# RZG2L register map
Vendor: Renesas; Series: All Chips; File version: x.xx
Registers are 32-bit, access not given, no defined reset value unless marked. A register's access mark holds for its fields unless they carry their own. Offsets are from the block's base; [hi:lo] are bit positions; {n}, {i} and the like mark numbered series; 'fields as' and 'values as' point back to an identical list.

## CPG
Base 0x41010000
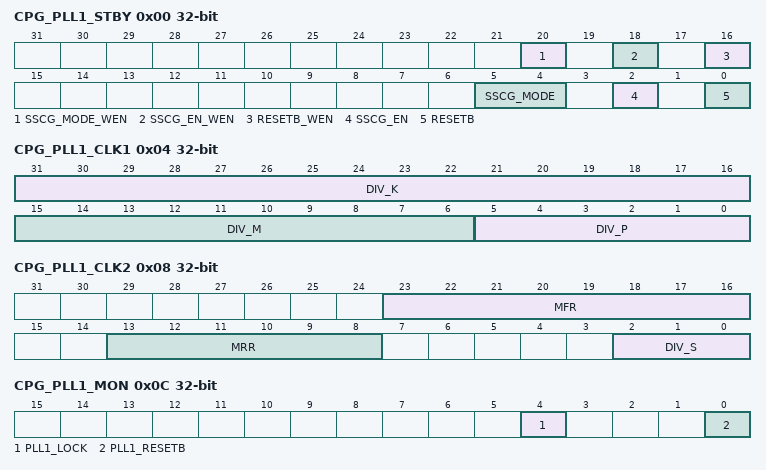
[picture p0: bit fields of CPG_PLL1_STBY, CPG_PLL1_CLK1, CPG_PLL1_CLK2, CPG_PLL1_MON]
0x00 CPG_PLL1_STBY
  [20] SSCG_MODE_WEN, [18] SSCG_EN_WEN, [16] RESETB_WEN, [5:4] SSCG_MODE, [2] SSCG_EN, [0] RESETB
0x04 CPG_PLL1_CLK1
  [31:16] DIV_K, [15:6] DIV_M, [5:0] DIV_P
0x08 CPG_PLL1_CLK2
  [23:16] MFR, [13:8] MRR, [2:0] DIV_S
0x0C CPG_PLL1_MON
  [4] PLL1_LOCK, [0] PLL1_RESETB
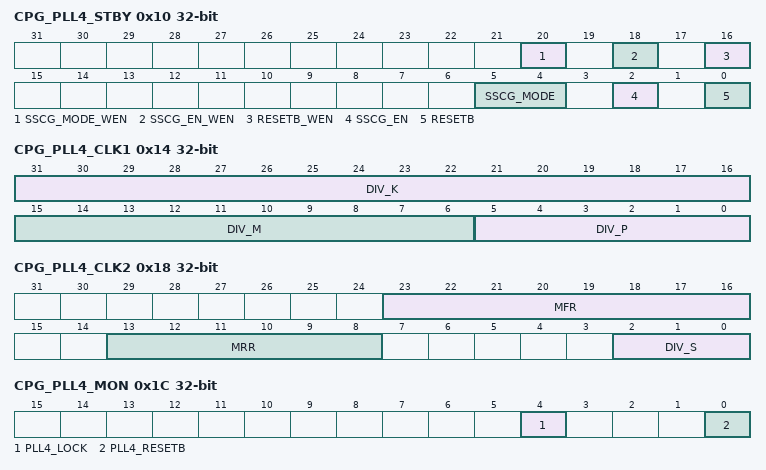
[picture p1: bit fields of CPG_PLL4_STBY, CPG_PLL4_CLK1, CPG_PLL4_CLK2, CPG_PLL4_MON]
0x10 CPG_PLL4_STBY
  fields as CPG_PLL1_STBY
0x14 CPG_PLL4_CLK1
  [31:16] DIV_K, [15:6] DIV_M, [5:0] DIV_P
0x18 CPG_PLL4_CLK2
  [23:16] MFR, [13:8] MRR, [2:0] DIV_S
0x1C CPG_PLL4_MON
  [4] PLL4_LOCK, [0] PLL4_RESETB
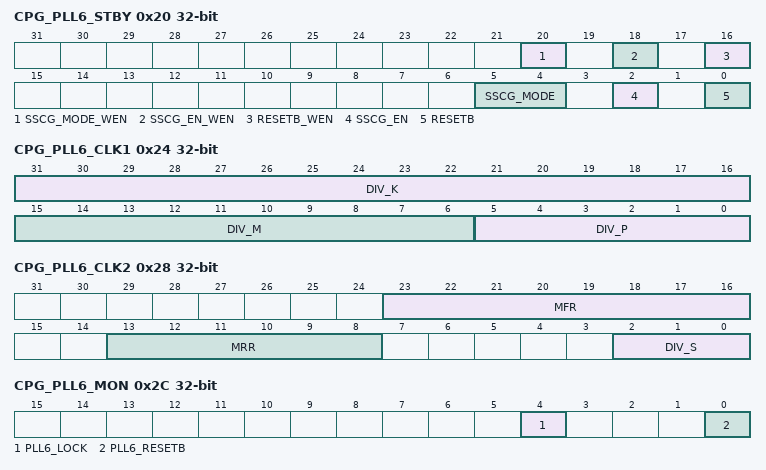
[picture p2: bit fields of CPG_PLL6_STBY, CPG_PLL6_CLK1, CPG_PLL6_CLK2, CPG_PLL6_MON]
0x20 CPG_PLL6_STBY
  fields as CPG_PLL1_STBY
0x24 CPG_PLL6_CLK1
  [31:16] DIV_K, [15:6] DIV_M, [5:0] DIV_P
0x28 CPG_PLL6_CLK2
  [23:16] MFR, [13:8] MRR, [2:0] DIV_S
0x2C CPG_PLL6_MON
  [4] PLL6_LOCK, [0] PLL6_RESETB
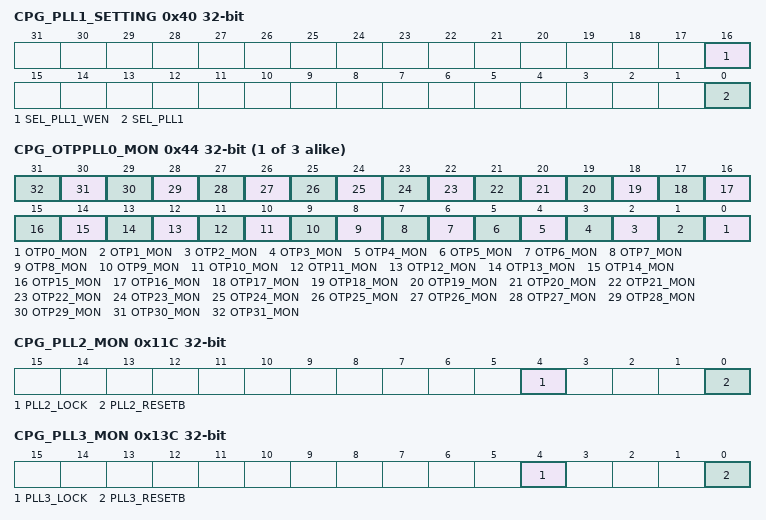
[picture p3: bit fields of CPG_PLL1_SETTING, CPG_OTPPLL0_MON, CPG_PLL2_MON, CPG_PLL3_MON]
0x40 CPG_PLL1_SETTING
  [16] SEL_PLL1_WEN, [0] SEL_PLL1
{0x44+4i} CPG_OTPPLL{i}_MON (i=0..2)
  [n] OTP{n}_MON (n=0..31)
0x11C CPG_PLL2_MON
  [4] PLL2_LOCK, [0] PLL2_RESETB
0x13C CPG_PLL3_MON
  [4] PLL3_LOCK, [0] PLL3_RESETB
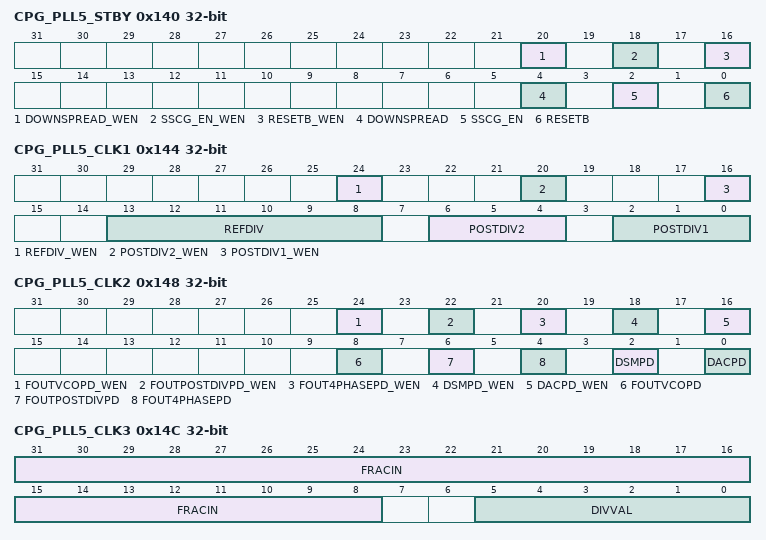
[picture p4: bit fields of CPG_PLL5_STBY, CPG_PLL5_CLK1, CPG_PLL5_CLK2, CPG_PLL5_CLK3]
0x140 CPG_PLL5_STBY
  [20] DOWNSPREAD_WEN, [18] SSCG_EN_WEN, [16] RESETB_WEN, [4] DOWNSPREAD, [2] SSCG_EN, [0] RESETB
0x144 CPG_PLL5_CLK1
  [24] REFDIV_WEN, [20] POSTDIV2_WEN, [16] POSTDIV1_WEN, [13:8] REFDIV, [6:4] POSTDIV2, [2:0] POSTDIV1
0x148 CPG_PLL5_CLK2
  [24] FOUTVCOPD_WEN, [22] FOUTPOSTDIVPD_WEN, [20] FOUT4PHASEPD_WEN, [18] DSMPD_WEN, [16] DACPD_WEN, [8] FOUTVCOPD, [6] FOUTPOSTDIVPD, [4] FOUT4PHASEPD, [2] DSMPD, [0] DACPD
0x14C CPG_PLL5_CLK3
  [31:8] FRACIN, [5:0] DIVVAL
0x150 CPG_PLL5_CLK4
  [27:16] INTIN
0x154 CPG_PLL5_CLK5
  [4:0] SPREAD
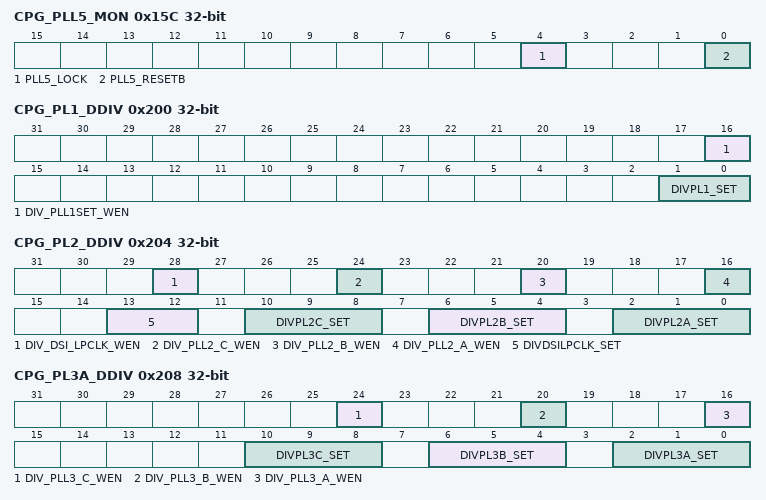
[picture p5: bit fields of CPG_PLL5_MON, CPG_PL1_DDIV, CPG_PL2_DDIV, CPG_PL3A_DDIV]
0x15C CPG_PLL5_MON
  [4] PLL5_LOCK, [0] PLL5_RESETB
0x200 CPG_PL1_DDIV
  [16] DIV_PLL1SET_WEN, [1:0] DIVPL1_SET
0x204 CPG_PL2_DDIV
  [28] DIV_DSI_LPCLK_WEN, [24] DIV_PLL2_C_WEN, [20] DIV_PLL2_B_WEN, [16] DIV_PLL2_A_WEN, [13:12] DIVDSILPCLK_SET, [10:8] DIVPL2C_SET, [6:4] DIVPL2B_SET, [2:0] DIVPL2A_SET
0x208 CPG_PL3A_DDIV
  [24] DIV_PLL3_C_WEN, [20] DIV_PLL3_B_WEN, [16] DIV_PLL3_A_WEN, [10:8] DIVPL3C_SET, [6:4] DIVPL3B_SET, [2:0] DIVPL3A_SET
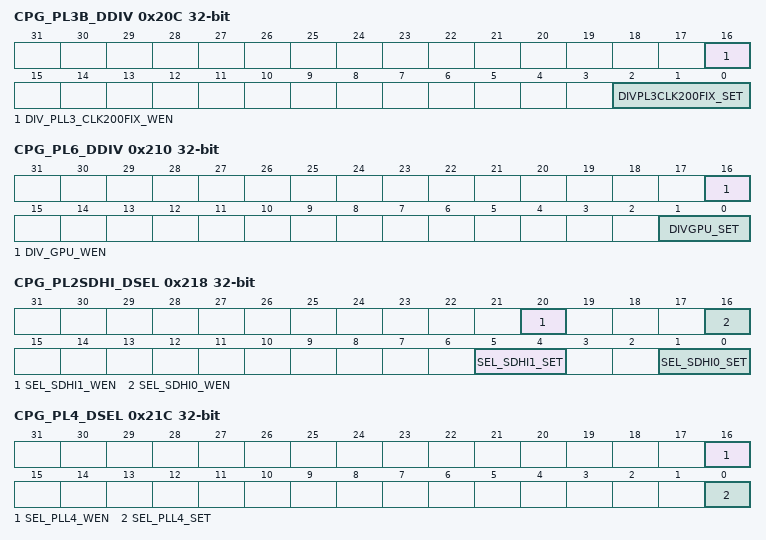
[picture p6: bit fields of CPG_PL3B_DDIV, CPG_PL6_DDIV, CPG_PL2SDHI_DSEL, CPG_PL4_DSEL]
0x20C CPG_PL3B_DDIV
  [16] DIV_PLL3_CLK200FIX_WEN, [2:0] DIVPL3CLK200FIX_SET
0x210 CPG_PL6_DDIV
  [16] DIV_GPU_WEN, [1:0] DIVGPU_SET
0x218 CPG_PL2SDHI_DSEL
  [20] SEL_SDHI1_WEN, [16] SEL_SDHI0_WEN, [5:4] SEL_SDHI1_SET, [1:0] SEL_SDHI0_SET
0x21C CPG_PL4_DSEL
  [16] SEL_PLL4_WEN, [0] SEL_PLL4_SET
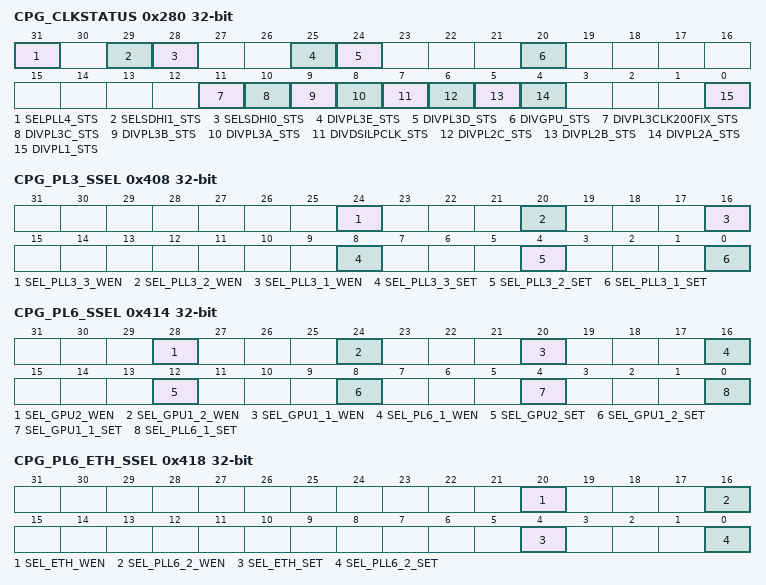
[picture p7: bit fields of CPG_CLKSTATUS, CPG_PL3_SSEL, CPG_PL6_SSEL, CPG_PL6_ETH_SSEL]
0x280 CPG_CLKSTATUS
  [31] SELPLL4_STS, [29] SELSDHI1_STS, [28] SELSDHI0_STS, [25] DIVPL3E_STS, [24] DIVPL3D_STS, [20] DIVGPU_STS, [11] DIVPL3CLK200FIX_STS, [10] DIVPL3C_STS, [9] DIVPL3B_STS, [8] DIVPL3A_STS, [7] DIVDSILPCLK_STS, [6] DIVPL2C_STS, [5] DIVPL2B_STS, [4] DIVPL2A_STS, [0] DIVPL1_STS
0x408 CPG_PL3_SSEL
  [24] SEL_PLL3_3_WEN, [20] SEL_PLL3_2_WEN, [16] SEL_PLL3_1_WEN, [8] SEL_PLL3_3_SET, [4] SEL_PLL3_2_SET, [0] SEL_PLL3_1_SET
0x414 CPG_PL6_SSEL
  [28] SEL_GPU2_WEN, [24] SEL_GPU1_2_WEN, [20] SEL_GPU1_1_WEN, [16] SEL_PL6_1_WEN, [12] SEL_GPU2_SET, [8] SEL_GPU1_2_SET, [4] SEL_GPU1_1_SET, [0] SEL_PLL6_1_SET
0x418 CPG_PL6_ETH_SSEL
  [20] SEL_ETH_WEN, [16] SEL_PLL6_2_WEN, [4] SEL_ETH_SET, [0] SEL_PLL6_2_SET
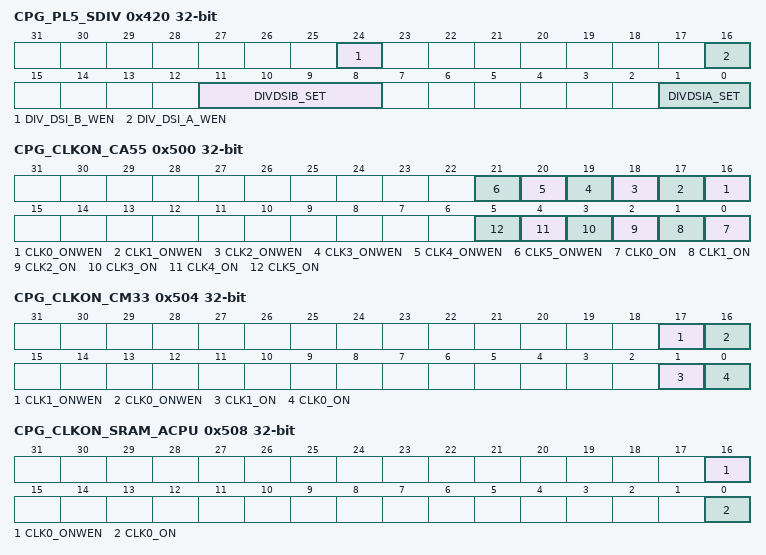
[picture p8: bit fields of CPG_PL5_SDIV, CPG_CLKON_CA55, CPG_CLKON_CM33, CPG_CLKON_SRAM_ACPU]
0x420 CPG_PL5_SDIV
  [24] DIV_DSI_B_WEN, [16] DIV_DSI_A_WEN, [11:8] DIVDSIB_SET, [1:0] DIVDSIA_SET
0x500 CPG_CLKON_CA55
  [n+16] CLK{n}_ONWEN (n=0..5), [n] CLK{n}_ON (n=0..5)
0x504 CPG_CLKON_CM33
  [17] CLK1_ONWEN, [16] CLK0_ONWEN, [1] CLK1_ON, [0] CLK0_ON
0x508 CPG_CLKON_SRAM_ACPU
  [16] CLK0_ONWEN, [0] CLK0_ON
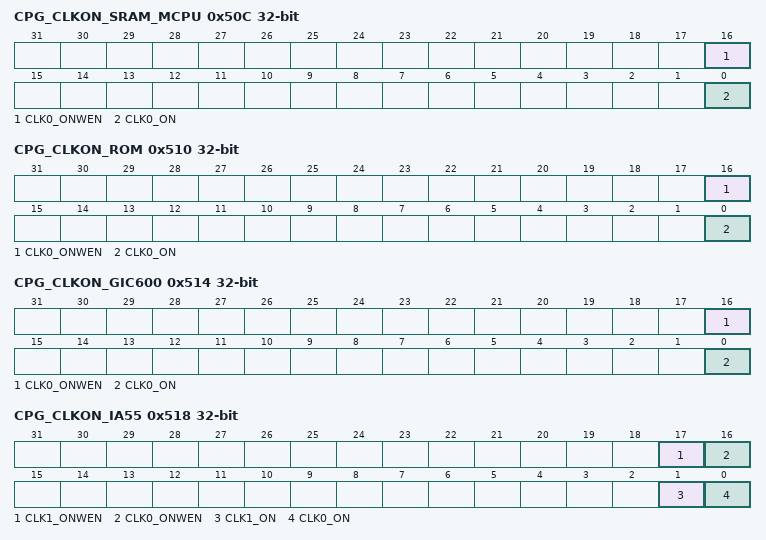
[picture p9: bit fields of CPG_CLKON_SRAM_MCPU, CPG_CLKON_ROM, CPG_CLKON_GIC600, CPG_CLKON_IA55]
0x50C CPG_CLKON_SRAM_MCPU
  [16] CLK0_ONWEN, [0] CLK0_ON
0x510 CPG_CLKON_ROM
  [16] CLK0_ONWEN, [0] CLK0_ON
0x514 CPG_CLKON_GIC600
  [16] CLK0_ONWEN, [0] CLK0_ON
0x518 CPG_CLKON_IA55
  [17] CLK1_ONWEN, [16] CLK0_ONWEN, [1] CLK1_ON, [0] CLK0_ON
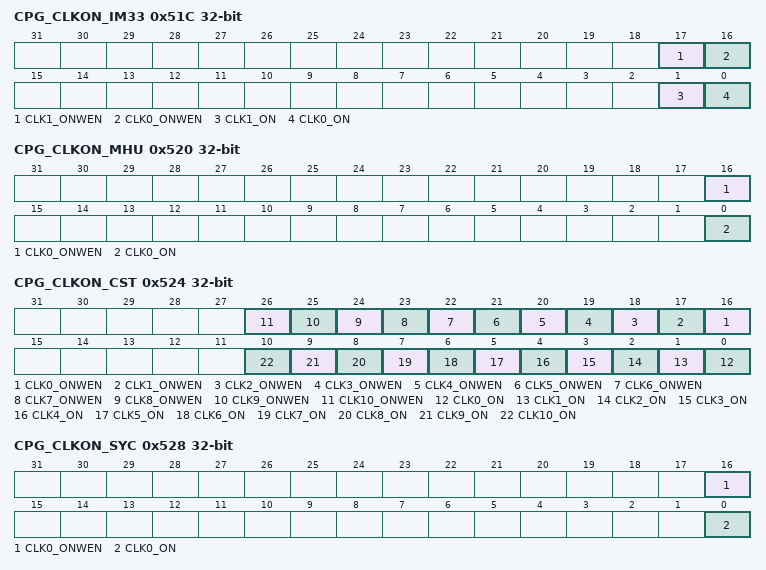
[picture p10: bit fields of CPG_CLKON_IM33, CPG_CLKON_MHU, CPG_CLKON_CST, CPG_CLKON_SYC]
0x51C CPG_CLKON_IM33
  [17] CLK1_ONWEN, [16] CLK0_ONWEN, [1] CLK1_ON, [0] CLK0_ON
0x520 CPG_CLKON_MHU
  [16] CLK0_ONWEN, [0] CLK0_ON
0x524 CPG_CLKON_CST
  [n+16] CLK{n}_ONWEN (n=0..10), [n] CLK{n}_ON (n=0..10)
0x528 CPG_CLKON_SYC
  [16] CLK0_ONWEN, [0] CLK0_ON
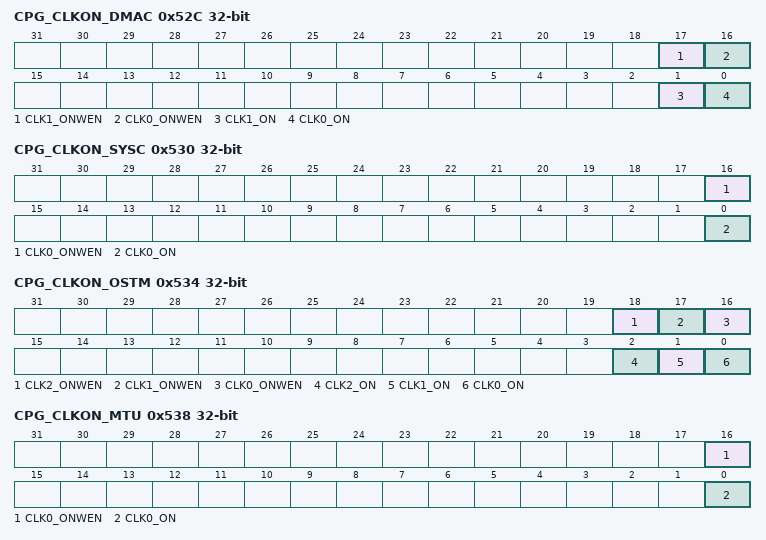
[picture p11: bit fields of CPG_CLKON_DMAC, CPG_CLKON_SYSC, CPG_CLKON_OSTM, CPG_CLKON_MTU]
0x52C CPG_CLKON_DMAC
  [17] CLK1_ONWEN, [16] CLK0_ONWEN, [1] CLK1_ON, [0] CLK0_ON
0x530 CPG_CLKON_SYSC
  [16] CLK0_ONWEN, [0] CLK0_ON
0x534 CPG_CLKON_OSTM
  [18] CLK2_ONWEN, [17] CLK1_ONWEN, [16] CLK0_ONWEN, [2] CLK2_ON, [1] CLK1_ON, [0] CLK0_ON
0x538 CPG_CLKON_MTU
  [16] CLK0_ONWEN, [0] CLK0_ON
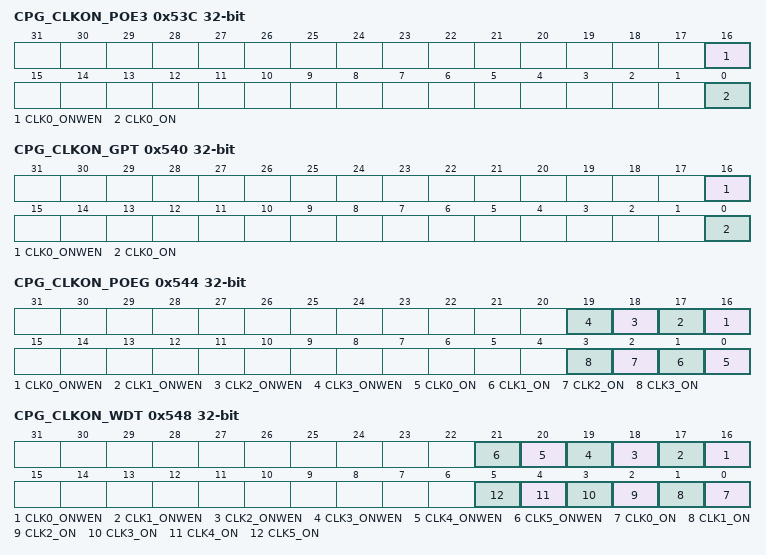
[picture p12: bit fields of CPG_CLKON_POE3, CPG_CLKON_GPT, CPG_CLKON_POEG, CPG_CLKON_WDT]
0x53C CPG_CLKON_POE3
  [16] CLK0_ONWEN, [0] CLK0_ON
0x540 CPG_CLKON_GPT
  [16] CLK0_ONWEN, [0] CLK0_ON
0x544 CPG_CLKON_POEG
  [n+16] CLK{n}_ONWEN (n=0..3), [n] CLK{n}_ON (n=0..3)
0x548 CPG_CLKON_WDT
  [n+16] CLK{n}_ONWEN (n=0..5), [n] CLK{n}_ON (n=0..5)
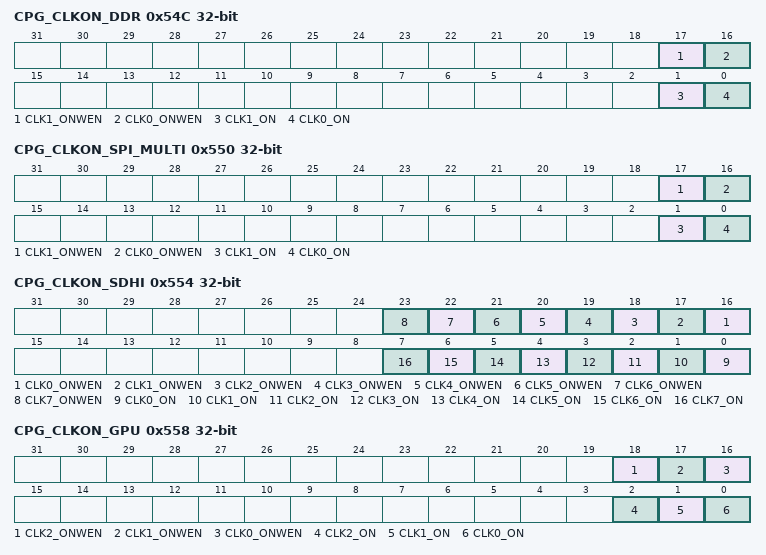
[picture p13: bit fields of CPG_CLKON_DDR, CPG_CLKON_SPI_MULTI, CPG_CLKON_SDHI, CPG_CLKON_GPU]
0x54C CPG_CLKON_DDR
  [17] CLK1_ONWEN, [16] CLK0_ONWEN, [1] CLK1_ON, [0] CLK0_ON
0x550 CPG_CLKON_SPI_MULTI
  [17] CLK1_ONWEN, [16] CLK0_ONWEN, [1] CLK1_ON, [0] CLK0_ON
0x554 CPG_CLKON_SDHI
  [n+16] CLK{n}_ONWEN (n=0..7), [n] CLK{n}_ON (n=0..7)
0x558 CPG_CLKON_GPU
  fields as CPG_CLKON_OSTM
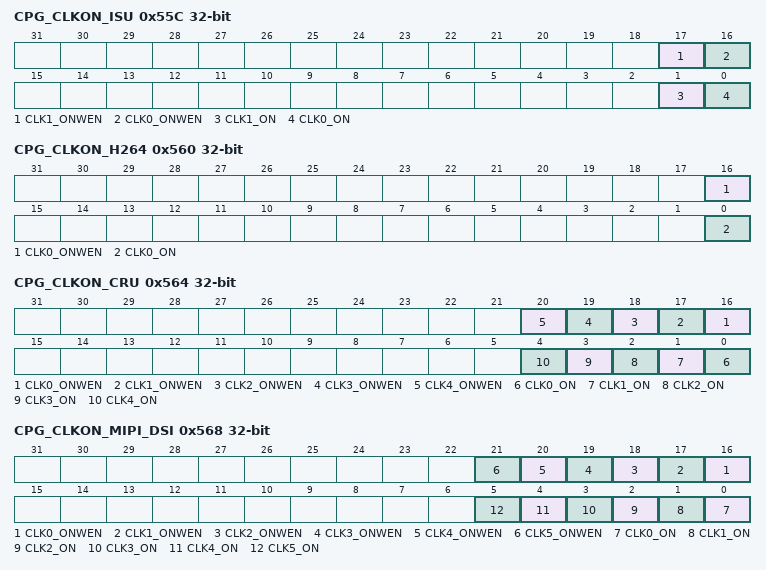
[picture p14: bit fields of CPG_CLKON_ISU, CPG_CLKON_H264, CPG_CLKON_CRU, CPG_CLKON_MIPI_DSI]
0x55C CPG_CLKON_ISU
  [17] CLK1_ONWEN, [16] CLK0_ONWEN, [1] CLK1_ON, [0] CLK0_ON
0x560 CPG_CLKON_H264
  [16] CLK0_ONWEN, [0] CLK0_ON
0x564 CPG_CLKON_CRU
  [n+16] CLK{n}_ONWEN (n=0..4), [n] CLK{n}_ON (n=0..4)
0x568 CPG_CLKON_MIPI_DSI
  [n+16] CLK{n}_ONWEN (n=0..5), [n] CLK{n}_ON (n=0..5)
0x56C CPG_CLKON_LCDC
  [17] CLK1_ONWEN, [16] CLK0_ONWEN, [1] CLK1_ON, [0] CLK0_ON
0x570 CPG_CLKON_SSIF
  [n+16] CLK{n}_ONWEN (n=0..7), [n] CLK{n}_ON (n=0..7)
0x574 CPG_CLKON_SRC
  [16] CLK0_ONWEN, [0] CLK0_ON
0x578 CPG_CLKON_USB
  [n+16] CLK{n}_ONWEN (n=0..3), [n] CLK{n}_ON (n=0..3)
0x57C CPG_CLKON_ETH
  [17] CLK1_ONWEN, [16] CLK0_ONWEN, [1] CLK1_ON, [0] CLK0_ON
0x580 CPG_CLKON_I2C
  [n+16] CLK{n}_ONWEN (n=0..3), [n] CLK{n}_ON (n=0..3)
0x584 CPG_CLKON_SCIF
  [n+16] CLK{n}_ONWEN (n=0..4), [n] CLK{n}_ON (n=0..4)
0x588 CPG_CLKON_SCI
  [17] CLK1_ONWEN, [16] CLK0_ONWEN, [1] CLK1_ON, [0] CLK0_ON
0x58C CPG_CLKON_IRDA
  [16] CLK0_ONWEN, [0] CLK0_ON
0x590 CPG_CLKON_RSPI
  fields as CPG_CLKON_OSTM
0x594 CPG_CLKON_CANFD
  [16] CLK0_ONWEN, [0] CLK0_ON
0x598 CPG_CLKON_GPIO
  [16] CLK0_ONWEN, [0] CLK0_ON
0x59C CPG_CLKON_TSIPG
  [17] CLK1_ONWEN, [16] CLK0_ONWEN, [1] CLK1_ON, [0] CLK0_ON
0x5A4 CPG_CLKON_OTP
  [17] CLK1_ONWEN, [16] CLK0_ONWEN, [1] CLK1_ON, [0] CLK0_ON
0x5A8 CPG_CLKON_ADC
  [17] CLK1_ONWEN, [16] CLK0_ONWEN, [1] CLK1_ON, [0] CLK0_ON
0x5AC CPG_CLKON_TSU
  [16] CLK0_ONWEN, [0] CLK0_ON
0x5B0 CPG_CLKON_BBGU
  [16] CLK0_ONWEN, [0] CLK0_ON
0x5B4 CPG_CLKON_AXI_ACPU_BUS
  [n+16] CLK{n}_ONWEN (n=0..3), [n] CLK{n}_ON (n=0..3)
0x5B8 CPG_CLKON_AXI_MCPU_BUS
  [n+16] CLK{n}_ONWEN (n=0..10), [n] CLK{n}_ON (n=0..10)
0x5BC CPG_CLKON_AXI_COM_BUS
  [17] CLK1_ONWEN, [16] CLK0_ONWEN, [1] CLK1_ON, [0] CLK0_ON
0x5C0 CPG_CLKON_AXI_VIDEO_BUS
  [17] CLK1_ONWEN, [16] CLK0_ONWEN, [1] CLK1_ON, [0] CLK0_ON
0x5C4 CPG_CLKON_PERI_COM
  [17] CLK1_ONWEN, [16] CLK0_ONWEN, [1] CLK1_ON, [0] CLK0_ON
0x5C8 CPG_CLKON_REG1_BUS
  [17] CLK1_ONWEN, [16] CLK0_ONWEN, [1] CLK1_ON, [0] CLK0_ON
0x5CC CPG_CLKON_REG0_BUS
  [n+16] CLK{n}_ONWEN (n=0..3), [n] CLK{n}_ON (n=0..3)
0x5D0 CPG_CLKON_PERI_CPU
  [n+16] CLK{n}_ONWEN (n=0..3), [n] CLK{n}_ON (n=0..3)
0x5D4 CPG_CLKON_PERI_VIDEO
  fields as CPG_CLKON_OSTM
0x5D8 CPG_CLKON_PERI_DDR
  [16] CLK0_ONWEN, [0] CLK0_ON
0x5DC CPG_CLKON_AXI_TZCDDR
  [n+16] CLK{n}_ONWEN (n=0..4), [n] CLK{n}_ON (n=0..4)
0x5E0 CPG_CLKON_MTGPGS
  [17] CLK1_ONWEN, [16] CLK0_ONWEN, [1] CLK1_ON, [0] CLK0_ON
0x5E4 CPG_CLKON_AXI_DEFAULT_SLV
  [16] CLK0_ONWEN, [0] CLK0_ON
0x680 CPG_CLKMON_CA55
  [n] CLK{n}_MON (n=0..5)
0x684 CPG_CLKMON_CM33
  [1] CLK1_MON, [0] CLK0_MON
0x688 CPG_CLKMON_SRAM_ACPU
  [0] CLK0_MON
0x68C CPG_CLKMON_SRAM_MCPU
  [0] CLK0_MON
0x690 CPG_CLKMON_ROM
  [0] CLK0_MON
0x694 CPG_CLKMON_GIC600
  [0] CLK0_MON
0x698 CPG_CLKMON_IA55
  [1] CLK1_MON, [0] CLK0_MON
0x69C CPG_CLKMON_IM33
  [1] CLK1_MON, [0] CLK0_MON
0x6A0 CPG_CLKMON_MHU
  [0] CLK0_MON
0x6A4 CPG_CLKMON_CST
  [n] CLK{n}_MON (n=0..10)
0x6A8 CPG_CLKMON_SYC
  [0] CLK0_MON
0x6AC CPG_CLKMON_DMAC
  [1] CLK1_MON, [0] CLK0_MON
0x6B0 CPG_CLKMON_SYSC
  [0] CLK0_MON
0x6B4 CPG_CLKMON_OSTM
  [2] CLK2_MON, [1] CLK1_MON, [0] CLK0_MON
0x6B8 CPG_CLKMON_MTU
  [0] CLK0_MON
0x6BC CPG_CLKMON_POE3
  [0] CLK0_MON
0x6C0 CPG_CLKMON_GPT
  [0] CLK0_MON
0x6C4 CPG_CLKMON_POEG
  [n] CLK{n}_MON (n=0..3)
0x6C8 CPG_CLKMON_WDT
  [n] CLK{n}_MON (n=0..7)
0x6CC CPG_CLKMON_DDR
  [1] CLK1_MON, [0] CLK0_MON
0x6D0 CPG_CLKMON_SPI_MULTI
  [1] CLK1_MON, [0] CLK0_MON
0x6D4 CPG_CLKMON_SDHI
  [n] CLK{n}_MON (n=0..7)
0x6D8 CPG_CLKMON_GPU
  [2] CLK2_MON, [1] CLK1_MON, [0] CLK0_MON
0x6DC CPG_CLKMON_ISU
  [1] CLK1_MON, [0] CLK0_MON
0x6E0 CPG_CLKMON_H264
  [0] CLK0_MON
0x6E4 CPG_CLKMON_CRU
  [n] CLK{n}_MON (n=0..4)
0x6E8 CPG_CLKMON_MIPI_DSI
  [n] CLK{n}_MON (n=0..5)
0x6EC CPG_CLKMON_LCDC
  [1] CLK1_MON, [0] CLK0_MON
0x6F0 CPG_CLKMON_SSIF
  [n] CLK{n}_MON (n=0..7)
0x6F4 CPG_CLKMON_SRC
  [0] CLK0_MON
0x6F8 CPG_CLKMON_USB
  [n] CLK{n}_MON (n=0..3)
0x6FC CPG_CLKMON_ETH
  [1] CLK1_MON, [0] CLK0_MON
0x700 CPG_CLKMON_I2C
  [n] CLK{n}_MON (n=0..3)
0x704 CPG_CLKMON_SCIF
  [n] CLK{n}_MON (n=0..4)
0x708 CPG_CLKMON_SCI
  [1] CLK1_MON, [0] CLK0_MON
0x70C CPG_CLKMON_IRDA
  [0] CLK0_MON
0x710 CPG_CLKMON_RSPI
  [2] CLK2_MON, [1] CLK1_MON, [0] CLK0_MON
0x714 CPG_CLKMON_CANFD
  [0] CLK0_MON
0x718 CPG_CLKMON_GPIO
  [0] CLK0_MON
0x71C CPG_CLKMON_TSIPG
  [1] CLK1_MON, [0] CLK0_MON
0x720 CPG_CLKMON_JAUTH
  [0] CLK0_MON
0x724 CPG_CLKMON_OTP
  [1] CLK1_MON, [0] CLK0_MON
0x728 CPG_CLKMON_ADC
  [1] CLK1_MON, [0] CLK0_MON
0x72C CPG_CLKMON_TSU
  [0] CLK0_MON
0x730 CPG_CLKMON_BBGU
  [0] CLK0_MON
0x734 CPG_CLKMON_AXI_ACPU_BUS
  [n] CLK{n}_MON (n=0..3)
0x738 CPG_CLKMON_AXI_MCPU_BUS
  [n] CLK{n}_MON (n=0..10)
0x73C CPG_CLKMON_AXI_COM_BUS
  [1] CLK1_MON, [0] CLK0_MON
0x740 CPG_CLKMON_AXI_VIDEO_BUS
  [1] CLK1_MON, [0] CLK0_MON
0x744 CPG_CLKMON_PERI_COM
  [1] CLK1_MON, [0] CLK0_MON
0x748 CPG_CLKMON_REG1_BUS
  [1] CLK1_MON, [0] CLK0_MON
0x74C CPG_CLKMON_REG0_BUS
  [n] CLK{n}_MON (n=0..3)
0x750 CPG_CLKMON_PERI_CPU
  [n] CLK{n}_MON (n=0..3)
0x754 CPG_CLKMON_PERI_VIDEO
  [2] CLK2_MON, [1] CLK1_MON, [0] CLK0_MON
0x758 CPG_CLKMON_PERI_DDR
  [0] CLK0_MON
0x75C CPG_CLKMON_AXI_TZCDDR
  [n] CLK{n}_MON (n=0..4)
0x760 CPG_CLKMON_MTGPGS
  [1] CLK1_MON, [0] CLK0_MON
0x764 CPG_CLKMON_AXI_DEFAULT_SLV
  [0] CLK0_MON
0x800 CPG_RST_CA55
  [n+16] UNIT{n}_RSTWEN (n=0..12), [n] UNIT{n}_RSTB (n=0..12)
0x804 CPG_RST_CM33
  [18] UNIT2_RSTWEN, [17] UNIT1_RSTWEN, [16] UNIT0_RSTWEN, [2] UNIT2_RSTB, [1] UNIT1_RSTB, [0] UNIT0_RSTB
0x808 CPG_RST_SRAM_ACPU
  [16] UNIT0_RSTWEN, [0] UNIT0_RSTB
0x80C CPG_RST_SRAM_MCPU
  [16] UNIT0_RSTWEN, [0] UNIT0_RSTB
0x810 CPG_RST_ROM
  [16] UNIT0_RSTWEN, [0] UNIT0_RSTB
0x814 CPG_RST_GIC600
  [17] UNIT1_RSTWEN, [16] UNIT0_RSTWEN, [1] UNIT1_RSTB, [0] UNIT0_RSTB
0x818 CPG_RST_IA55
  [16] UNIT0_RSTWEN, [0] UNIT0_RSTB
0x81C CPG_RST_IM33
  [16] UNIT0_RSTWEN, [0] UNIT0_RSTB
0x820 CPG_RST_MHU
  [16] UNIT0_RSTWEN, [0] UNIT0_RSTB
0x828 CPG_RST_SYC
  [16] UNIT0_RSTWEN, [0] UNIT0_RSTB
0x82C CPG_RST_DMAC
  [17] UNIT1_RSTWEN, [16] UNIT0_RSTWEN, [1] UNIT1_RSTB, [0] UNIT0_RSTB
0x830 CPG_RST_SYSC
  fields as CPG_RST_CM33
0x834 CPG_RST_OSTM
  fields as CPG_RST_CM33
0x838 CPG_RST_MTU
  [16] UNIT0_RSTWEN, [0] UNIT0_RSTB
0x83C CPG_RST_POE3
  [16] UNIT0_RSTWEN, [0] UNIT0_RSTB
0x840 CPG_RST_GPT
  [16] UNIT0_RSTWEN, [0] UNIT0_RSTB
0x844 CPG_RST_POEG
  [n+16] UNIT{n}_RSTWEN (n=0..3), [n] UNIT{n}_RSTB (n=0..3)
0x848 CPG_RST_WDT
  [n+16] UNIT{n}_RSTWEN (n=0..3), [n] UNIT{n}_RSTB (n=0..3)
0x84C CPG_RST_DDR
  [n+16] UNIT{n}_RSTWEN (n=0..6), [n] UNIT{n}_RSTB (n=0..6)
0x850 CPG_RST_SPI
  [16] UNIT0_RSTWEN, [0] UNIT0_RSTB
0x854 CPG_RST_SDHI
  [17] UNIT1_RSTWEN, [16] UNIT0_RSTWEN, [1] UNIT1_RSTB, [0] UNIT0_RSTB
0x858 CPG_RST_GPU
  fields as CPG_RST_CM33
0x85C CPG_RST_ISU
  [17] UNIT1_RSTWEN, [16] UNIT0_RSTWEN, [1] UNIT1_RSTB, [0] UNIT0_RSTB
0x860 CPG_RST_H264
  [17] UNIT1_RSTWEN, [16] UNIT0_RSTWEN, [1] UNIT1_RSTB, [0] UNIT0_RSTB
0x864 CPG_RST_CRU
  fields as CPG_RST_CM33
0x868 CPG_RST_MIPI_DSI
  fields as CPG_RST_CM33
0x86C CPG_RST_LCDC
  [16] UNIT0_RSTWEN, [0] UNIT0_RSTB
0x870 CPG_RST_SSIF
  [n+16] UNIT{n}_RSTWEN (n=0..3), [n] UNIT{n}_RSTB (n=0..3)
0x874 CPG_RST_SRC
  [16] UNIT0_RSTWEN, [0] UNIT0_RSTB
0x878 CPG_RST_USB
  [n+16] UNIT{n}_RSTWEN (n=0..3), [n] UNIT{n}_RSTB (n=0..3)
0x87C CPG_RST_ETH
  [17] UNIT1_RSTWEN, [16] UNIT0_RSTWEN, [1] UNIT1_RSTB, [0] UNIT0_RSTB
0x880 CPG_RST_I2C
  [n+16] UNIT{n}_RSTWEN (n=0..3), [n] UNIT{n}_RSTB (n=0..3)
0x884 CPG_RST_SCIF
  [n+16] UNIT{n}_RSTWEN (n=0..4), [n] UNIT{n}_RSTB (n=0..4)
0x888 CPG_RST_SCI
  [17] UNIT1_RSTWEN, [16] UNIT0_RSTWEN, [1] UNIT1_RSTB, [0] UNIT0_RSTB
0x88C CPG_RST_IRDA
  [16] UNIT0_RSTWEN, [0] UNIT0_RSTB
0x890 CPG_RST_RSPI
  fields as CPG_RST_CM33
0x894 CPG_RST_CANFD
  [17] UNIT1_RSTWEN, [16] UNIT0_RSTWEN, [1] UNIT1_RSTB, [0] UNIT0_RSTB
0x898 CPG_RST_GPIO
  fields as CPG_RST_CM33
0x89C CPG_RST_TSIPG
  [16] UNIT0_RSTWEN, [0] UNIT0_RSTB
0x8A0 CPG_RST_JAUTH
  [16] UNIT0_RSTWEN, [0] UNIT0_RSTB
0x8A4 CPG_RST_OTP
  [16] UNIT0_RSTWEN, [0] UNIT0_RSTB
0x8A8 CPG_RST_ADC
  [17] UNIT1_RSTWEN, [16] UNIT0_RSTWEN, [1] UNIT1_RSTB, [0] UNIT0_RSTB
0x8AC CPG_RST_TSU
  [16] UNIT0_RSTWEN, [0] UNIT0_RSTB
0x8B0 CPG_RST_BBGU
  [16] UNIT0_RSTWEN, [0] UNIT0_RSTB
0x8B4 CPG_RST_AXI_ACPU_BUS
  [16] UNIT0_RSTWEN, [0] UNIT0_RSTB
0x8B8 CPG_RST_AXI_MCPU_BUS
  [16] UNIT0_RSTWEN, [0] UNIT0_RSTB
0x8BC CPG_RST_AXI_COM_BUS
  [16] UNIT0_RSTWEN, [0] UNIT0_RSTB
0x8C0 CPG_RST_AXI_VIDEO_BUS
  [16] UNIT0_RSTWEN, [0] UNIT0_RSTB
0x8C4 CPG_RST_PERI_COM
  [16] UNIT0_RSTWEN, [0] UNIT0_RSTB
0x8C8 CPG_RST_REG1_BUS
  [16] UNIT0_RSTWEN, [0] UNIT0_RSTB
0x8CC CPG_RST_REG0_BUS
  [16] UNIT0_RSTWEN, [0] UNIT0_RSTB
0x8D0 CPG_RST_PERI_CPU
  [16] UNIT0_RSTWEN, [0] UNIT0_RSTB
0x8D4 CPG_RST_PERI_VIDEO
  [16] UNIT0_RSTWEN, [0] UNIT0_RSTB
0x8D8 CPG_RST_PERI_DDR
  [16] UNIT0_RSTWEN, [0] UNIT0_RSTB
0x8DC CPG_RST_AXI_TZCDDR
  [n+16] UNIT{n}_RSTWEN (n=0..4), [n] UNIT{n}_RSTB (n=0..4)
0x8E0 CPG_RST_MTGPGS
  [17] UNIT1_RSTWEN, [16] UNIT0_RSTWEN, [1] UNIT1_RSTB, [0] UNIT0_RSTB
0x8E4 CPG_RST_AXI_DEFAULT_SLV
  [16] UNIT0_RSTWEN, [0] UNIT0_RSTB
0x980 CPG_RSTMON_CA55
  [n] RST{n}_MON (n=0..12)
0x984 CPG_RSTMON_CM33
  [2] RST2_MON, [1] RST1_MON, [0] RST0_MON
0x988 CPG_RSTMON_SRAM_ACPU
  [0] RST0_MON
0x98C CPG_RSTMON_SRAM_MCPU
  [0] RST0_MON
0x990 CPG_RSTMON_ROM
  [0] RST0_MON
0x994 CPG_RSTMON_GIC600
  [1] RST1_MON, [0] RST0_MON
0x998 CPG_RSTMON_IA55
  [0] RST0_MON
0x99C CPG_RSTMON_IM33
  [0] RST0_MON
0x9A0 CPG_RSTMON_MHU
  [0] RST0_MON
0x9A8 CPG_RSTMON_SYC
  [0] RST0_MON
0x9AC CPG_RSTMON_DMAC
  [1] RST1_MON, [0] RST0_MON
0x9B0 CPG_RSTMON_SYSC
  [2] RST2_MON, [1] RST1_MON, [0] RST0_MON
0x9B4 CPG_RSTMON_OSTM
  [2] RST2_MON, [1] RST1_MON, [0] RST0_MON
0x9B8 CPG_RSTMON_MTU
  [0] RST0_MON
0x9BC CPG_RSTMON_POE3
  [0] RST0_MON
0x9C0 CPG_RSTMON_GPT
  [0] RST0_MON
0x9C4 CPG_RSTMON_POEG
  [n] RST{n}_MON (n=0..3)
0x9C8 CPG_RSTMON_WDT
  [n] RST{n}_MON (n=0..3)
0x9CC CPG_RSTMON_DDR
  [n] RST{n}_MON (n=0..6)
0x9D0 CPG_RSTMON_SPI
  [0] RST0_MON
0x9D4 CPG_RSTMON_SDHI
  [1] RST1_MON, [0] RST0_MON
0x9D8 CPG_RSTMON_GPU
  [2] RST2_MON, [1] RST1_MON, [0] RST0_MON
0x9DC CPG_RSTMON_ISU
  [1] RST1_MON, [0] RST0_MON
0x9E0 CPG_RSTMON_H264
  [1] RST1_MON, [0] RST0_MON
0x9E4 CPG_RSTMON_CRU
  [2] RST2_MON, [1] RST1_MON, [0] RST0_MON
0x9E8 CPG_RSTMON_MIPI_DSI
  [2] RST2_MON, [1] RST1_MON, [0] RST0_MON
0x9EC CPG_RSTMON_LCDC
  [0] RST0_MON
0x9F0 CPG_RSTMON_SSIF
  [n] RST{n}_MON (n=0..3)
0x9F4 CPG_RSTMON_SRC
  [0] RST0_MON
0x9F8 CPG_RSTMON_USB
  [n] RST{n}_MON (n=0..3)
0x9FC CPG_RSTMON_ETH
  [1] RST1_MON, [0] RST0_MON
0xA00 CPG_RSTMON_I2C
  [n] RST{n}_MON (n=0..3)
0xA04 CPG_RSTMON_SCIF
  [n] RST{n}_MON (n=0..4)
0xA08 CPG_RSTMON_SCI
  [1] RST1_MON, [0] RST0_MON
0xA0C CPG_RSTMON_IRDA
  [0] RST0_MON
0xA10 CPG_RSTMON_RSPI
  [2] RST2_MON, [1] RST1_MON, [0] RST0_MON
0xA14 CPG_RSTMON_CANFD
  [1] RST1_MON, [0] RST0_MON
0xA18 CPG_RSTMON_GPIO
  [2] RST2_MON, [1] RST1_MON, [0] RST0_MON
0xA1C CPG_RSTMON_TSIPG
  [0] RST0_MON
0xA20 CPG_RSTMON_JAUTH
  [0] RST0_MON
0xA24 CPG_RSTMON_OTP
  [0] RST0_MON
0xA28 CPG_RSTMON_ADC
  [1] RST1_MON, [0] RST0_MON
0xA2C CPG_RSTMON_TSU
  [0] RST0_MON
0xA30 CPG_RSTMON_BBGU
  [0] RST0_MON
0xA34 CPG_RSTMON_AXI_ACPU_BUS
  [0] RST0_MON
0xA38 CPG_RSTMON_AXI_MCPU_BUS
  [0] RST0_MON
0xA3C CPG_RSTMON_AXI_COM_BUS
  [0] RST0_MON
0xA40 CPG_RSTMON_AXI_VIDEO_BUS
  [0] RST0_MON
0xA44 CPG_RSTMON_PERI_COM
  [0] RST0_MON
0xA48 CPG_RSTMON_REG1_BUS
  [0] RST0_MON
0xA4C CPG_RSTMON_REG0_BUS
  [0] RST0_MON
0xA50 CPG_RSTMON_PERI_CPU
  [0] RST0_MON
0xA54 CPG_RSTMON_PERI_VIDEO
  [0] RST0_MON
0xA58 CPG_RSTMON_PERI_DDR
  [0] RST0_MON
0xA5C CPG_RSTMON_AXI_TZCDDR
  [n] RST{n}_MON (n=0..4)
0xA60 CPG_RSTMON_MTGPGS
  [1] RST1_MON, [0] RST0_MON
0xA64 CPG_RSTMON_AXI_DEFAULT_SLV
  [0] RST0_MON
0xB00 CPG_EN_OSTM
  [18] EN2WEN, [17] EN1WEN, [16] EN0WEN, [2] EN2_ON, [1] EN1_ON, [0] EN0_ON
0xB10 CPG_WDTOVF_RST
  [18] WDTOVF2_WEN, [17] WDTOVF1_WEN, [16] WDTOVF0_WEN, [2] WDTOVF2, [1] WDTOVF1, [0] WDTOVF0
0xB14 CPG_WDTRST_SEL
  [26] WDTRSTSEL10_WEN, [25] WDTRSTSEL9_WEN, [24] WDTRSTSEL8_WEN, [22] WDTRSTSEL6_WEN, [21] WDTRSTSEL5_WEN, [20] WDTRSTSEL4_WEN, [18] WDTRSTSEL2_WEN, [17] WDTRSTSEL1_WEN, [16] WDTRSTSEL0_WEN, [10] WDTRSTSEL10, [9] WDTRSTSEL9, [8] WDTRSTSEL8, [6] WDTRSTSEL6, [5] WDTRSTSEL5, [4] WDTRSTSEL4, [2] WDTRSTSEL2, [1] WDTRSTSEL1, [0] WDTRSTSEL0
0xB30 CPG_CLUSTER_PCHMON
  [1] PDENY_MON, [0] PACCEPT_MON
0xB34 CPG_CLUSTER_PCHCTL
  [22:16] PSTATE0_SET, [0] PREQ_SET
0xB38 CPG_CORE0_PCHMON
  [1] PDENY0_MON, [0] PACCEPT0_MON
0xB3C CPG_CORE0_PCHCTL
  [21:16] PSTATE0_SET, [0] PREQ0_SET
0xB40 CPG_CORE1_PCHMON
  [1] PDENY1_MON, [0] PACCEPT1_MON
0xB44 CPG_CORE1_PCHCTL
  [21:16] PSTATE1_SET, [0] PREQ1_SET
0xB60 CPG_BUS_ACPU_MSTOP
  [16] MSTOP0_ON_WEN, [0] MSTOP0_ON
0xB64 CPG_BUS_MCPU1_MSTOP
  [n+16] MSTOP{n}_ON_WEN (n=6..15), [n+16] MSTOP{n}_ON_WEN (n=0..4), [n] MSTOP{n}_ON (n=0..15)
0xB68 CPG_BUS_MCPU2_MSTOP
  [n+16] MSTOP{n}_ON_WEN (n=0..15), [n] MSTOP{n}_ON (n=0..15)
0xB6C CPG_BUS_PERI_COM_MSTOP
  [n+16] MSTOP{n}_ON_WEN (n=0..8), [n] MSTOP{n}_ON (n=0..8)
0xB70 CPG_BUS_PERI_CPU_MSTOP
  [n+16] MSTOP{n}_ON_WEN (n=0..15), [n] MSTOP{n}_ON (n=6..15), [n] MSTOP{n}_ON (n=0..4)
0xB74 CPG_BUS_PERI_DDR_MSTOP
  [17] MSTOP1_ON_WEN, [16] MSTOP0_ON_WEN, [1] MSTOP1_ON, [0] MSTOP0_ON
0xB78 CPG_BUS_PERI_VIDEO_MSTOP
  [n+16] MSTOP{n}_ON_WEN (n=0..10), [n] MSTOP{n}_ON (n=0..10)
0xB7C CPG_BUS_REG0_MSTOP
  [n+16] MSTOP{n}_ON_WEN (n=0..6), [n] MSTOP{n}_ON (n=0..6)
0xB80 CPG_BUS_REG1_MSTOP
  [n+16] MSTOP{n}_ON_WEN (n=0..7), [n] MSTOP{n}_ON (n=0..7)
0xB84 CPG_BUS_TZCDDR_MSTOP
  [n+16] MSTOP{n}_ON_WEN (n=0..3), [n] MSTOP{n}_ON (n=0..3)
0xB88 CPG_MHU_MSTOP
  [16] MSTOP0_ON_WEN, [0] MSTOP0_ON
0xBE8 CPG_OTHERFUNC1_REG
  [n+16] RES{n}_ON_WEN (n=0..15), [n] RES{n}_SET (n=0..15)
0xBEC CPG_OTHERFUNC2_REG
  [n+16] RES{n}_ON_WEN (n=0..15), [n] RES{n}_SET (n=0..15)
